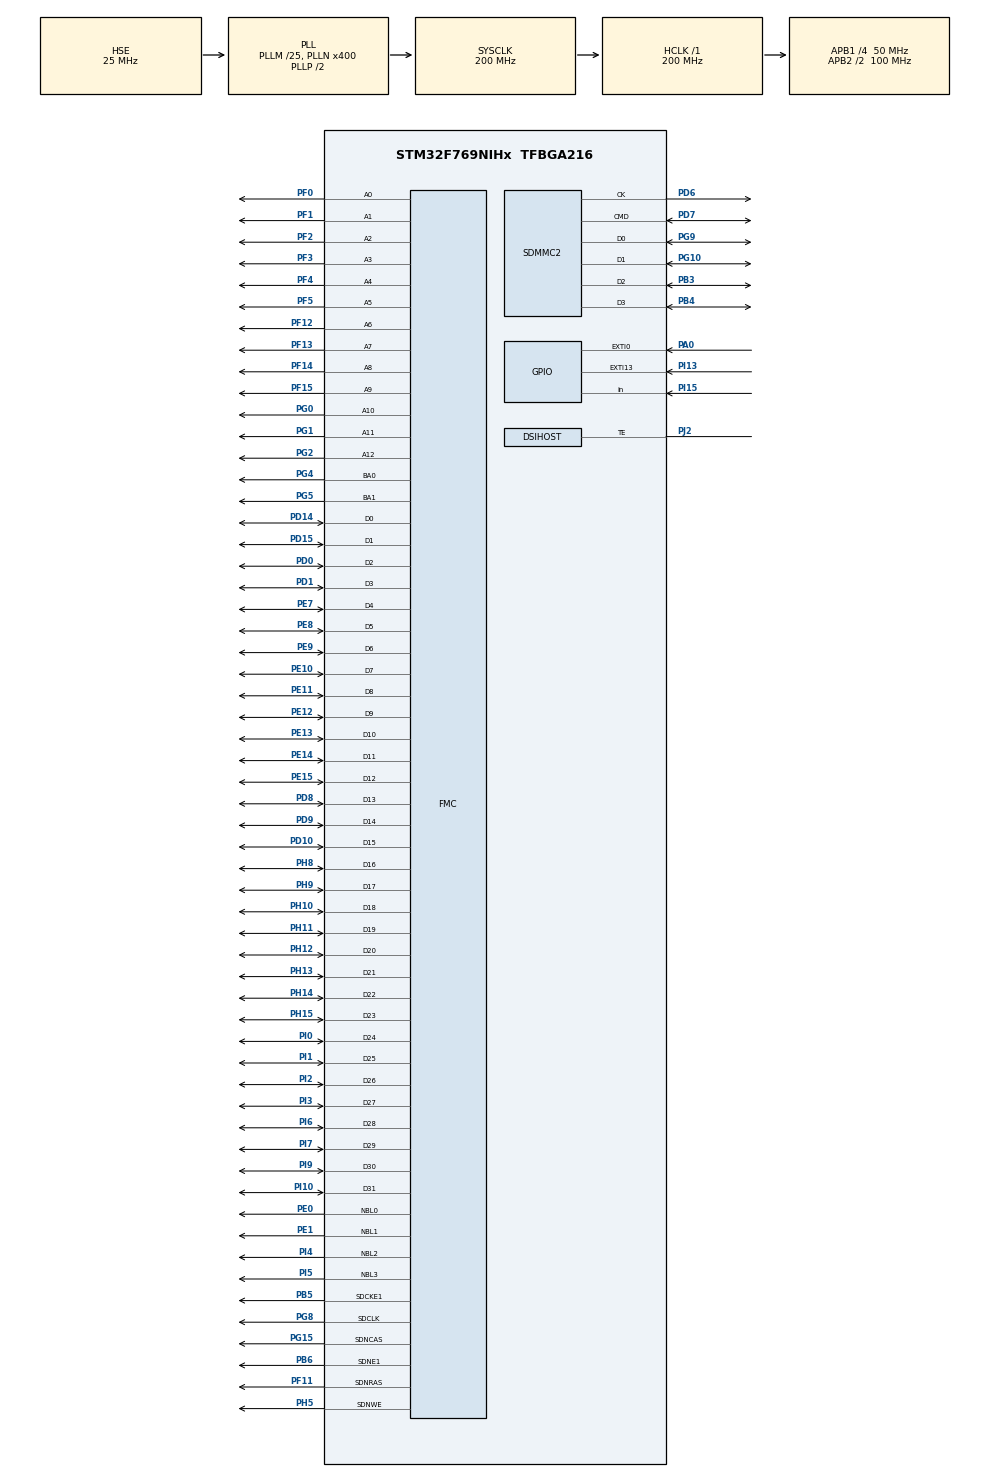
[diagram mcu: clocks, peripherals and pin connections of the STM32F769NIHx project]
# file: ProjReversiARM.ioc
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ADC1.Channel-0\#ChannelRegularConversion=ADC_CHANNEL_TEMPSENSOR
ADC1.ContinuousConvMode=ENABLE
ADC1.EOCSelection=ADC_EOC_SEQ_CONV
ADC1.NbrOfConversionFlag=1
ADC1.Rank-0\#ChannelRegularConversion=1
ADC1.SamplingTime-0\#ChannelRegularConversion=ADC_SAMPLETIME_56CYCLES
ADC1.master=1
CORTEX_M7.CPU_DCache=Enabled
CORTEX_M7.CPU_ICache=Enabled
DSIHOST_CKN.Mode=DSIHost_Adapted_TE
DSIHOST_CKN.Signal=DSIHOST_CKN
DSIHOST_CKP.Mode=DSIHost_Adapted_TE
DSIHOST_CKP.Signal=DSIHOST_CKP
DSIHOST_D0N.Mode=DSIHost_Adapted_TE
DSIHOST_D0N.Signal=DSIHOST_D0N
DSIHOST_D0P.Mode=DSIHost_Adapted_TE
DSIHOST_D0P.Signal=DSIHOST_D0P
DSIHOST_D1N.Mode=DSIHost_Adapted_TE
DSIHOST_D1N.Signal=DSIHOST_D1N
DSIHOST_D1P.Mode=DSIHost_Adapted_TE
DSIHOST_D1P.Signal=DSIHOST_D1P
FATFS.BSP.number=1
FATFS0.BSP.STBoard=false
FATFS0.BSP.api=Unknown
FATFS0.BSP.i2caddr=0
FATFS0.BSP.instance=PI15
FATFS0.BSP.ip=GPIO
FATFS0.BSP.mode=Input
FATFS0.BSP.name=Detect_SDIO
FATFS0.BSP.solution=PI15
Mcu.Family=STM32F7
Mcu.Name=STM32F769NIHx
Mcu.Package=TFBGA216
NVIC.EXTI0_IRQn=true\:0\:0\:false\:false\:true\:true\:true
NVIC.EXTI15_10_IRQn=true\:0\:0\:false\:false\:true\:true\:true
NVIC.PriorityGroup=NVIC_PRIORITYGROUP_4
NVIC.TIM6_DAC_IRQn=true\:0\:0\:false\:false\:true\:true\:true
NVIC.TIM7_IRQn=true\:0\:0\:false\:false\:true\:true\:true
PA0/WKUP.Signal=GPXTI0
PB3.Mode=SD_4_bits_Wide_bus
PB3.Signal=SDMMC2_D2
PB4.Mode=SD_4_bits_Wide_bus
PB4.Signal=SDMMC2_D3
PB5.Mode=SdramChipSelect2_1
PB5.Signal=FMC_SDCKE1
PB6.Mode=SdramChipSelect2_1
PB6.Signal=FMC_SDNE1
PD0.Signal=FMC_D2_DA2
PD1.Signal=FMC_D3_DA3
PD10.Signal=FMC_D15_DA15
PD14.Signal=FMC_D0_DA0
PD15.Signal=FMC_D1_DA1
PD6.Mode=SD_4_bits_Wide_bus
PD6.Signal=SDMMC2_CK
PD7.Mode=SD_4_bits_Wide_bus
PD7.Signal=SDMMC2_CMD
PD8.Signal=FMC_D13_DA13
PD9.Signal=FMC_D14_DA14
PE0.Signal=FMC_NBL0
PE1.Signal=FMC_NBL1
PE10.Signal=FMC_D7_DA7
PE11.Signal=FMC_D8_DA8
PE12.Signal=FMC_D9_DA9
PE13.Signal=FMC_D10_DA10
PE14.Signal=FMC_D11_DA11
PE15.Signal=FMC_D12_DA12
PE7.Signal=FMC_D4_DA4
PE8.Signal=FMC_D5_DA5
PE9.Signal=FMC_D6_DA6
PF0.Signal=FMC_A0
PF1.Signal=FMC_A1
PF11.Signal=FMC_SDNRAS
PF12.Signal=FMC_A6
PF13.Signal=FMC_A7
PF14.Signal=FMC_A8
PF15.Signal=FMC_A9
PF2.Signal=FMC_A2
PF3.Signal=FMC_A3
PF4.Signal=FMC_A4
PF5.Signal=FMC_A5
PG0.Signal=FMC_A10
PG1.Signal=FMC_A11
PG10.Mode=SD_4_bits_Wide_bus
PG10.Signal=SDMMC2_D1
PG15.Signal=FMC_SDNCAS
PG2.Signal=FMC_A12
PG4.Signal=FMC_A14_BA0
PG5.Signal=FMC_A15_BA1
PG8.Signal=FMC_SDCLK
PG9.Mode=SD_4_bits_Wide_bus
PG9.Signal=SDMMC2_D0
PH0/OSC_IN.Mode=HSE-External-Oscillator
PH0/OSC_IN.Signal=RCC_OSC_IN
PH1/OSC_OUT.Mode=HSE-External-Oscillator
PH1/OSC_OUT.Signal=RCC_OSC_OUT
PH10.Signal=FMC_D18
PH11.Signal=FMC_D19
PH12.Signal=FMC_D20
PH13.Signal=FMC_D21
PH14.Signal=FMC_D22
PH15.Signal=FMC_D23
PH5.Signal=FMC_SDNWE
PH8.Signal=FMC_D16
PH9.Signal=FMC_D17
PI0.Signal=FMC_D24
PI1.Signal=FMC_D25
PI10.Signal=FMC_D31
PI13.Signal=GPXTI13
PI15.Signal=GPIO_Input
PI2.Signal=FMC_D26
PI3.Signal=FMC_D27
PI4.Signal=FMC_NBL2
PI5.Signal=FMC_NBL3
PI6.Signal=FMC_D28
PI7.Signal=FMC_D29
PI9.Signal=FMC_D30
PJ2.Mode=DSIHost_Adapted_TE
PJ2.Signal=DSIHOST_TE
ProjectManager.HeapSize=0x200
ProjectManager.StackSize=0x400
ProjectManager.TargetToolchain=STM32CubeIDE
RCC.AHBFreq_Value=200000000
RCC.APB1CLKDivider=RCC_HCLK_DIV4
RCC.APB1Freq_Value=50000000
RCC.APB1TimFreq_Value=100000000
RCC.APB2CLKDivider=RCC_HCLK_DIV2
RCC.APB2Freq_Value=100000000
RCC.APB2TimFreq_Value=200000000
RCC.CortexFreq_Value=200000000
RCC.HCLKFreq_Value=200000000
RCC.HSE_VALUE=25000000
RCC.HSI_VALUE=16000000
RCC.LSE_VALUE=32768
RCC.PLLI2SN=96
RCC.PLLM=25
RCC.PLLN=400
RCC.PLLQ=8
RCC.PLLSourceVirtual=RCC_PLLSOURCE_HSE
RCC.SDMMC2ClockSelection=RCC_SDMMC2CLKSOURCE_CLK48
RCC.SYSCLKFreq_VALUE=200000000
RCC.SYSCLKSource=RCC_SYSCLKSOURCE_PLLCLK
RCC.USBFreq_Value=50000000
RCC.VCOOutputFreq_Value=400000000
SH.FMC_A0.0=FMC_A0,13b-sda1
SH.FMC_A1.0=FMC_A1,13b-sda1
SH.FMC_A10.0=FMC_A10,13b-sda1
SH.FMC_A11.0=FMC_A11,13b-sda1
SH.FMC_A12.0=FMC_A12,13b-sda1
SH.FMC_A14_BA0.0=FMC_BA0,FourSdramBanks1
SH.FMC_A15_BA1.0=FMC_BA1,FourSdramBanks1
SH.FMC_A2.0=FMC_A2,13b-sda1
SH.FMC_A3.0=FMC_A3,13b-sda1
SH.FMC_A4.0=FMC_A4,13b-sda1
SH.FMC_A5.0=FMC_A5,13b-sda1
SH.FMC_A6.0=FMC_A6,13b-sda1
SH.FMC_A7.0=FMC_A7,13b-sda1
SH.FMC_A8.0=FMC_A8,13b-sda1
SH.FMC_A9.0=FMC_A9,13b-sda1
SH.FMC_D0_DA0.0=FMC_D0,sd-32b-d1
SH.FMC_D10_DA10.0=FMC_D10,sd-32b-d1
SH.FMC_D11_DA11.0=FMC_D11,sd-32b-d1
SH.FMC_D12_DA12.0=FMC_D12,sd-32b-d1
SH.FMC_D13_DA13.0=FMC_D13,sd-32b-d1
SH.FMC_D14_DA14.0=FMC_D14,sd-32b-d1
SH.FMC_D15_DA15.0=FMC_D15,sd-32b-d1
SH.FMC_D16.0=FMC_D16,sd-32b-d1
SH.FMC_D17.0=FMC_D17,sd-32b-d1
SH.FMC_D18.0=FMC_D18,sd-32b-d1
SH.FMC_D19.0=FMC_D19,sd-32b-d1
SH.FMC_D1_DA1.0=FMC_D1,sd-32b-d1
SH.FMC_D20.0=FMC_D20,sd-32b-d1
SH.FMC_D21.0=FMC_D21,sd-32b-d1
SH.FMC_D22.0=FMC_D22,sd-32b-d1
SH.FMC_D23.0=FMC_D23,sd-32b-d1
SH.FMC_D24.0=FMC_D24,sd-32b-d1
SH.FMC_D25.0=FMC_D25,sd-32b-d1
SH.FMC_D26.0=FMC_D26,sd-32b-d1
SH.FMC_D27.0=FMC_D27,sd-32b-d1
SH.FMC_D28.0=FMC_D28,sd-32b-d1
SH.FMC_D29.0=FMC_D29,sd-32b-d1
SH.FMC_D2_DA2.0=FMC_D2,sd-32b-d1
SH.FMC_D30.0=FMC_D30,sd-32b-d1
SH.FMC_D31.0=FMC_D31,sd-32b-d1
SH.FMC_D3_DA3.0=FMC_D3,sd-32b-d1
SH.FMC_D4_DA4.0=FMC_D4,sd-32b-d1
SH.FMC_D5_DA5.0=FMC_D5,sd-32b-d1
SH.FMC_D6_DA6.0=FMC_D6,sd-32b-d1
SH.FMC_D7_DA7.0=FMC_D7,sd-32b-d1
SH.FMC_D8_DA8.0=FMC_D8,sd-32b-d1
SH.FMC_D9_DA9.0=FMC_D9,sd-32b-d1
SH.FMC_NBL0.0=FMC_NBL0,Sd4ByteEnable1
SH.FMC_NBL1.0=FMC_NBL1,Sd4ByteEnable1
SH.FMC_NBL2.0=FMC_NBL2,Sd4ByteEnable1
SH.FMC_NBL3.0=FMC_NBL3,Sd4ByteEnable1
SH.FMC_SDCLK.0=FMC_SDCLK,13b-sda1
SH.FMC_SDNCAS.0=FMC_SDNCAS,13b-sda1
SH.FMC_SDNRAS.0=FMC_SDNRAS,13b-sda1
SH.FMC_SDNWE.0=FMC_SDNWE,13b-sda1
TIM6.Period=9999
TIM6.Prescaler=9999
TIM7.Period=9999
TIM7.Prescaler=9999
VP_ADC1_TempSens_Input.Mode=IN-TempSens
VP_DMA2D_VS_DMA2D.Mode=DMA2D_Activate
VP_FATFS_VS_SDIO.Mode=SDIO
VP_LTDC_DSIMode.Mode=RGB888
VP_TIM6_VS_ClockSourceINT.Mode=Enable_Timer
VP_TIM7_VS_ClockSourceINT.Mode=Enable_Timer
board=STM32F769I-DISC1

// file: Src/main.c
/* USER CODE BEGIN Header */
/**
  ******************************************************************************
  * @file           : main.c
  * @brief          : Main program body
  ******************************************************************************
  * @attention
  *
  * <h2><center>&copy; Copyright (c) 2019 STMicroelectronics.
  * All rights reserved.</center></h2>
  *
  * This software component is licensed by ST under BSD 3-Clause license,
  * the "License"; You may not use this file except in compliance with the
  * License. You may obtain a copy of the License at:
  *                        opensource.org/licenses/BSD-3-Clause
  *
  ******************************************************************************
  */
/* USER CODE END Header */

#include "main.h"
#include "fatfs.h"

/* USER CODE BEGIN Includes */
#include <stdio.h>
#include "stm32f769i_discovery_lcd.h"
#include "stm32f769i_discovery_ts.h"
#include "stm32f769i_discovery.h"
#include <stdbool.h>
#include "imgBlack.h"
//#include "imgRed.h"
/* USER CODE END Includes */

/* USER CODE BEGIN PD */
#define TEMP_REFRESH_PERIOD   1000    /* Internal temperature refresh period */
#define MAX_CONVERTED_VALUE   4095    /* Max converted value */
#define AMBIENT_TEMP            25    /* Ambient Temperature */
#define VSENS_AT_AMBIENT_TEMP  760    /* VSENSE value (mv) at ambient temperature */
#define AVG_SLOPE               25    /* Avg_Solpe multiply by 10 */
#define VREF                   3300
#define TAMQUADRADO				56.3
#define X				TS_State.touchX[0]
#define Y				TS_State.touchY[0]
#define RAIO					22
/* USER CODE END PD */

ADC_HandleTypeDef hadc1;

DMA2D_HandleTypeDef hdma2d;

DSI_HandleTypeDef hdsi;

LTDC_HandleTypeDef hltdc;

SD_HandleTypeDef hsd2;

TIM_HandleTypeDef htim6;
TIM_HandleTypeDef htim7;

SDRAM_HandleTypeDef hsdram1;

/* USER CODE BEGIN PV */

TS_StateTypeDef TS_State;

volatile uint32_t ConvertedValue;
volatile uint8_t tempCnt = 0;		//contador para alterar a temperatura a cada 2 segundos
volatile int timeTotal=0;			//contador do tempo total de jogo
volatile uint8_t seconds = 0;		//contador para converter o tempo total em segundos
volatile uint8_t minutes=0;			//contador para os minutos do tempo total
volatile uint8_t ctdown=20;			//contador do tempo de jogada
volatile uint8_t touchCircle=0;		//contador de toques da peça branca
volatile uint8_t touchFill=0;		//contador de toques da peça preta
volatile uint8_t ctJogadas=0;		//contador para o numero de jogadas
volatile uint8_t ctTimeOut=3;		//contador para o numero de timeouts
volatile uint8_t ctReset=0;			//contador para o umero de resets

long int JTemp;						//variavel para guardar a temperatura
char string[50];
int reset=0;
int passouTempo=0;

//FLAGS
volatile uint8_t DBFLAG=0; 				//flag para debouncing
bool TEMPFLAG=false;					//flag para entrar na temperatura
volatile uint8_t PLAYERFLAG=0;			//flag para trocar jogador
volatile uint8_t TIMEFLAG=0;			//flag para contador decrescente
volatile uint8_t MENUFLAG=0;			//flag para entrar no menu
volatile uint8_t UPDATE_DISPLAY = 0;	//flag para update display
volatile uint8_t LETSPLAY=0;			//flag para iniciar o jogo
bool VERMELHAJOGOU=false;				//flag para saber se branca jogou numa celula
bool PRETAJOGOU=false;					//flag para saber se preta jogou numa celula

/* USER CODE END PV */

void SystemClock_Config(void);
static void MX_GPIO_Init(void);
static void MX_ADC1_Init(void);
static void MX_DMA2D_Init(void);
static void MX_DSIHOST_DSI_Init(void);
static void MX_FMC_Init(void);
static void MX_LTDC_Init(void);
static void MX_SDMMC2_SD_Init(void);
static void MX_TIM6_Init(void);
static void MX_TIM7_Init(void);
/* USER CODE BEGIN PFP */
static void LCD_Config();
/* USER CODE END PFP */

/* USER CODE BEGIN 0 */
void HAL_GPIO_EXTI_Callback(uint16_t GPIO_Pin){

	if(GPIO_Pin==GPIO_PIN_0){
		reset=1;
	}

	if(GPIO_Pin==GPIO_PIN_13)
	{
		if(DBFLAG == 0)
		{
			DBFLAG=1;
			UPDATE_DISPLAY = 1;
			BSP_TS_GetState(&TS_State);
		}
	}
}

//GOAL 1 //temperatura
void temperatura() {
	uint32_t ConvertedValue;
	char desc[100];

	if(tempCnt >= 2)
	{
		tempCnt = 0;

		HAL_StatusTypeDef status = HAL_ADC_PollForConversion(&hadc1, TEMP_REFRESH_PERIOD);
		if (status == HAL_OK) {
			ConvertedValue = HAL_ADC_GetValue(&hadc1); //get value
			JTemp = ((((ConvertedValue * VREF) / MAX_CONVERTED_VALUE)- VSENS_AT_AMBIENT_TEMP) * 10 / AVG_SLOPE) + AMBIENT_TEMP;

			/* Display the Temperature Value on the LCD */
			sprintf(desc, "Temp: %ldC", JTemp);
			//BSP_LCD_FillRect(BSP_LCD_GetXSize()-160, 0, (uint8_t *) desc, LEFT_MODE);
			BSP_LCD_SetBackColor(LCD_COLOR_YELLOW);
			BSP_LCD_DisplayStringAt(BSP_LCD_GetXSize()-160, 0, (uint8_t *) desc, LEFT_MODE);
			BSP_LCD_ClearStringLine(BSP_LCD_GetXSize()-160);
		}
	}
}

//GOAL6 //saveSD
void saveSD(){

	char toques[500];
	uint nbytes;

	sprintf(toques,"Peça vermelha: %d toques Peça preta: %d toques / Tempo decorrido %02d:%02d / Temperatura: %ldC / Nº de resets: %d",touchCircle, touchFill, minutes, seconds, JTemp, ctReset);
	/*sprintf(toques,"Peca branca: %d toques / ",touchCircle);
	sprintf(toques,"Peca preta: %d toques / ",touchFill);
	sprintf(toques,"Tempo decorrido %02d:%02d",minutes,seconds);*/

	if(f_mount(&SDFatFS, SDPath, 0)!= FR_OK)
		Error_Handler();
	if(f_open(&SDFile, "toques.txt", FA_WRITE | FA_OPEN_ALWAYS) != FR_OK)
		Error_Handler();
	else
		BSP_LED_Toggle(LED_GREEN);
	if(f_write(&SDFile, toques, strlen(toques), &nbytes) != FR_OK)
		Error_Handler();
	else{
		BSP_LED_Toggle(LED_GREEN);
		HAL_Delay(250);
	}

	f_close(&SDFile);
}

/*void readSD(){
	if(f_mount(&SDFatFS, SDPath, 0)!= FR_OK)
		Error_Handler();
	if(f_open(&SDFile, "toques.txt", FA_WRITE | FA_OPEN_ALWAYS) != FR_OK){
		Error_Handler();
		BSP_LED_Toggle(LED_GREEN);
		HAL_Delay(250);
	}
	if(f_read(&SDFile, toques, strlen(toques), &nbytes) != FR_OK){
		Error_Handler();
		BSP_LED_Toggle(LED_GREEN);
		HAL_Delay(250);
	}
	BSP_LCD_DisplayStringAtLine(1, (uint8_t*)toques);
	f_close(&SDFile);
}*/

void drawPiece(int i, int j){

	if(DBFLAG == 1){
		HAL_Delay(100);
		DBFLAG=0;

		if(PLAYERFLAG==0){
			BSP_LCD_SetTextColor(LCD_COLOR_RED);
			BSP_LCD_FillCircle(i+(TAMQUADRADO/2), j+(TAMQUADRADO/2), RAIO);
			PLAYERFLAG=1;
			touchCircle++;
			ctJogadas++;
			VERMELHAJOGOU=true;
			BSP_LCD_SetTextColor(LCD_COLOR_BLACK);
		}
		else{
			BSP_LCD_SetTextColor(LCD_COLOR_BLACK);
			BSP_LCD_FillCircle(i+(TAMQUADRADO/2), j+(TAMQUADRADO/2), RAIO);
			PLAYERFLAG=0;
			touchFill++;
			ctJogadas++;
			PRETAJOGOU=true;
			BSP_LCD_SetTextColor(LCD_COLOR_BLACK);
		}
		if(ctJogadas==11){
			saveSD();
		}
	}
}

//GOAL 3 //limites
void limites()
{
	int i=0, j=0;

	/*memset(string, '\0', 50);
	sprintf(string, "X= %d", X);
	BSP_LCD_ClearStringLine(4);
	BSP_LCD_DisplayStringAtLine(4, (uint8_t *)string);

	memset(string, '\0', 50);
	sprintf(string, "Y= %d", Y);
	BSP_LCD_ClearStringLine(5);
	BSP_LCD_DisplayStringAtLine(5, (uint8_t *)string);*/

	for(i=0; i<BSP_LCD_GetXSize()-360; i+=TAMQUADRADO)
	{
		for(j=30;j<BSP_LCD_GetYSize()-30;j+=TAMQUADRADO)
		{
			if(X<BSP_LCD_GetXSize()-360  && X >= 0 && Y>30 && Y<BSP_LCD_GetYSize())
			{
				if(X>i && X<(i+TAMQUADRADO) && Y>j && Y<(j+TAMQUADRADO))
				{
					drawPiece(i,j);
					break;
				}
			}
			else
				DBFLAG=0;
		}
	}
}

//GOAL 2 //tab
void tab(){
	int i=0, j=30;
	/*int x=BSP_LCD_GetXSize()/2;
	int y=BSP_LCD_GetYSize();*/

	for(i=0; i<BSP_LCD_GetXSize()-360; i+=TAMQUADRADO)
	{
		/*BSP_LCD_SetTextColor(LCD_COLOR_GREEN);
		BSP_LCD_FillRect(i, 30, TAMQUADRADO, TAMQUADRADO);
		BSP_LCD_SetTextColor(LCD_COLOR_BLACK);*/
		BSP_LCD_DrawRect(i, 30, TAMQUADRADO, TAMQUADRADO);

		for(j=30;j<BSP_LCD_GetYSize()-30;j+=TAMQUADRADO){
			/*BSP_LCD_SetTextColor(LCD_COLOR_GREEN);
			BSP_LCD_FillRect(i, j, TAMQUADRADO, TAMQUADRADO);
			BSP_LCD_SetTextColor(LCD_COLOR_BLACK);*/
			BSP_LCD_DrawRect(i, j, TAMQUADRADO, TAMQUADRADO);
		}
		if(i>168.9 && i<225.2 && j>142.6 && j<198.9)
			BSP_LCD_DrawCircle(i+(TAMQUADRADO/2), j+(TAMQUADRADO/2), RAIO);
	}

	//limites();
}

//GOAL 4

//GOAL 5 //menu
void menu(){

	char escolha[50];
	BSP_LCD_Clear(LCD_COLOR_WHITE);
	MENUFLAG=1;

	sprintf(escolha,"PLAYER vs PLAYER");
	BSP_LCD_DrawRect(BSP_LCD_GetXSize()-565, BSP_LCD_GetYSize()-400, 350, 60);
	BSP_LCD_DisplayStringAt(BSP_LCD_GetXSize()-525, BSP_LCD_GetYSize()-375, (uint8_t *) escolha, LEFT_MODE);
	BSP_LCD_ClearStringLine(BSP_LCD_GetXSize()-525);

	sprintf(escolha, "PLAYER vs CPU");
	BSP_LCD_DrawRect(BSP_LCD_GetXSize()-540, BSP_LCD_GetYSize()-265, 300, 60);
	BSP_LCD_DisplayStringAt(BSP_LCD_GetXSize()-500, BSP_LCD_GetYSize()-240, (uint8_t *) escolha, LEFT_MODE);
	BSP_LCD_ClearStringLine(BSP_LCD_GetXSize()-500);

	while(DBFLAG != 1)	//Enquanto n tocar no lcd
	{
		HAL_Delay(100);
	}

	if(X>=BSP_LCD_GetXSize()-565 && X<=BSP_LCD_GetYSize()-25 && Y>=BSP_LCD_GetYSize()-400 && Y<=BSP_LCD_GetYSize()-340)
	{
		MENUFLAG=0;
		UPDATE_DISPLAY=1;
		//LCD_Config();
		//LETSPLAY=1;
		BSP_LCD_Clear(LCD_COLOR_WHITE);
		//joga();
	}
	/*if(X==BSP_LCD_GetXSize()-500 && Y==BSP_LCD_GetYSize()-240){
	 	MENUFLAG=1;
	 	UPDATE_DISPLAY=1;
		jogaAI();
	}*/

}

//GOAL7	//countdown
void countDown()
{
	char t[50];
	char to[50];
	char win[50];

	if(PLAYERFLAG==0){
		sprintf(t, "Countdown: %02ds", ctdown);
		sprintf(to,"Timeouts %d", ctTimeOut);
		if(ctdown>10){
			BSP_LCD_SetBackColor(LCD_COLOR_GREEN);
			BSP_LCD_DisplayStringAt(BSP_LCD_GetXSize()-290, 55, (uint8_t *)t, LEFT_MODE);
			BSP_LCD_SetBackColor(LCD_COLOR_WHITE);
			BSP_LCD_DisplayStringAt(BSP_LCD_GetXSize()-290, 85, (uint8_t *)to, LEFT_MODE);
		}
		if(ctdown<=10 && ctdown>5){
			BSP_LCD_SetBackColor(LCD_COLOR_YELLOW);
			BSP_LCD_DisplayStringAt(BSP_LCD_GetXSize()-290, 55, (uint8_t *)t, LEFT_MODE);
			BSP_LCD_SetBackColor(LCD_COLOR_WHITE);
			BSP_LCD_DisplayStringAt(BSP_LCD_GetXSize()-290, 85, (uint8_t *)to, LEFT_MODE);
		}
		if(ctdown<=5){
			BSP_LCD_SetBackColor(LCD_COLOR_RED);
			BSP_LCD_DisplayStringAt(BSP_LCD_GetXSize()-290, 55, (uint8_t *)t, LEFT_MODE);
			BSP_LCD_SetBackColor(LCD_COLOR_WHITE);
			BSP_LCD_DisplayStringAt(BSP_LCD_GetXSize()-290, 85, (uint8_t *)to, LEFT_MODE);
		}
		if(ctdown==0){
			passouTempo++;
			ctdown=20;
			ctTimeOut--;
			PLAYERFLAG=1;
		}
		if(ctTimeOut==0){
			BSP_LCD_SetBackColor(LCD_COLOR_WHITE);
			sprintf(win,"BLACK WINS");
			BSP_LCD_DisplayStringAt(BSP_LCD_GetXSize()-290, BSP_LCD_GetYSize()/2, (uint8_t *)win, LEFT_MODE);
			//BSP_LCD_Clear(LCD_COLOR_WHITE);
			BSP_LCD_DrawBitmap(BSP_LCD_GetXSize()-290,BSP_LCD_GetYSize()/2,(uint8_t*) stlogo);
			LETSPLAY=0;
			saveSD();
		}
	}

	if(PLAYERFLAG==1){
		sprintf(t, "Countdown: %02ds", ctdown);
		sprintf(to,"Timeouts %d", ctTimeOut);
		if(ctdown>10){
			BSP_LCD_SetBackColor(LCD_COLOR_GREEN);
			BSP_LCD_DisplayStringAt(BSP_LCD_GetXSize()-290, 55, (uint8_t *)t, LEFT_MODE);
			BSP_LCD_SetBackColor(LCD_COLOR_WHITE);
			BSP_LCD_DisplayStringAt(BSP_LCD_GetXSize()-290, 85, (uint8_t *)to, LEFT_MODE);
		}
		if(ctdown<=10 && ctdown>5){
			BSP_LCD_SetBackColor(LCD_COLOR_YELLOW);
			BSP_LCD_DisplayStringAt(BSP_LCD_GetXSize()-290, 55, (uint8_t *)t, LEFT_MODE);
			BSP_LCD_SetBackColor(LCD_COLOR_WHITE);
			BSP_LCD_DisplayStringAt(BSP_LCD_GetXSize()-290, 85, (uint8_t *)to, LEFT_MODE);
		}
		if(ctdown<=5){
			BSP_LCD_SetBackColor(LCD_COLOR_RED);
			BSP_LCD_DisplayStringAt(BSP_LCD_GetXSize()-290, 55, (uint8_t *)t, LEFT_MODE);
			BSP_LCD_SetBackColor(LCD_COLOR_WHITE);
			BSP_LCD_DisplayStringAt(BSP_LCD_GetXSize()-290, 85, (uint8_t *)to, LEFT_MODE);
		}
		if(ctdown==0){
			ctdown=20;
			ctTimeOut--;
			PLAYERFLAG=0;
		}
		if(ctTimeOut==0){
			BSP_LCD_SetBackColor(LCD_COLOR_WHITE);
			sprintf(win,"RED WINS");
			BSP_LCD_DisplayStringAt(BSP_LCD_GetXSize()-290, BSP_LCD_GetYSize()/2, (uint8_t *)win, LEFT_MODE);
			//BSP_LCD_Clear(LCD_COLOR_WHITE);
			//BSP_LCD_DrawBitmap(BSP_LCD_GetXSize()-290,BSP_LCD_GetYSize()/2,(uint8_t*) stlogo);
			LETSPLAY=0;
			saveSD();
		}
	}
	BSP_LCD_SetBackColor(LCD_COLOR_WHITE);
}

//GOAL8	//tempoJogo
void tempoJogo(){

	char t[50];

	if(TIMEFLAG==0)
	{
		sprintf(t, "Total Time: %02d:%02d", minutes, seconds);
		BSP_LCD_SetBackColor(LCD_COLOR_WHITE);
		BSP_LCD_DisplayStringAt(BSP_LCD_GetXSize()-290, 31, (uint8_t *)t, LEFT_MODE);

		if(seconds>59)
		{
			minutes++;
			seconds=0;
		}
	}
}

//GOAL 9	//restart
void restart(){
	BSP_LCD_Clear(LCD_COLOR_WHITE);
	menu();

	ConvertedValue;
	tempCnt = 0;
	timeTotal=0;
	seconds = 0;
	minutes=0;
	ctdown=20;
	touchCircle=0;
	touchFill=0;
	ctJogadas=0;
	ctTimeOut=3;
	ctReset=0;

	reset=0;
	passouTempo=0;

	//FLAGS
	DBFLAG=0;
	TEMPFLAG=false;
	PLAYERFLAG=0;
	TIMEFLAG=0;
	MENUFLAG=0;
	UPDATE_DISPLAY = 0;
	//LETSPLAY=0;
	VERMELHAJOGOU=false;
	PRETAJOGOU=false;
}

//funcoes de apoio
void joga(){
	//BSP_LCD_Clear(LCD_COLOR_WHITE);
	temperatura();
	tab();
	tempoJogo();
	if(ctJogadas==11){
		saveSD();
		//restart();
		menu();
	}
	if(reset==1)
	  restart();
}

void jogaAI(){

}

void getTouch(){
	if(DBFLAG == 1)
		  {
			  DBFLAG = 0;
			  memset(string, '\0', 50);
			  sprintf(string, "X= %d", TS_State.touchX[0]);
			  BSP_LCD_ClearStringLine(4);
			  BSP_LCD_DisplayStringAtLine(4, (uint8_t *)string);

			  memset(string, '\0', 50);
			  sprintf(string, "Y= %d", TS_State.touchY[0]);
			  BSP_LCD_ClearStringLine(5);
			  BSP_LCD_DisplayStringAtLine(5, (uint8_t *)string);

		  }
}
/*void header(){
	BSP_LCD_SetTextColor(LCD_COLOR_WHITE);
	BSP_LCD_SetBackColor(LCD_COLOR_BLUE);
	BSP_LCD_SetFont(&Font24);
	BSP_LCD_DisplayStringAt(0, 5, (uint8_t *)"REVERSI PROJECT", CENTER_MODE);
}*/

/* USER CODE END 0 */

int main(void)
{

  /* Enable I-Cache---------------------------------------------------------*/
  SCB_EnableICache();

  /* Enable D-Cache---------------------------------------------------------*/
  SCB_EnableDCache();

  /* MCU Configuration--------------------------------------------------------*/

  /* Reset of all peripherals, Initializes the Flash interface and the Systick. */
  HAL_Init();

  /* Configure the system clock */
  SystemClock_Config();

  /* Initialize all configured peripherals */
  MX_GPIO_Init();
  MX_ADC1_Init();
  MX_DMA2D_Init();
  MX_DSIHOST_DSI_Init();
  MX_FMC_Init();
  MX_LTDC_Init();
  MX_SDMMC2_SD_Init();
  MX_TIM6_Init();
  MX_TIM7_Init();
  MX_FATFS_Init();
  /* USER CODE BEGIN 2 */
  LCD_Config();
  	//BSP_LED_Init(LED1);

  BSP_TS_Init(BSP_LCD_GetXSize(), BSP_LCD_GetYSize());
  BSP_TS_ITConfig();

  	//start do adc
  	HAL_ADC_Start(&hadc1);
  	//HAL_ADC_Start_IT(&hadc3);

  	HAL_TIM_Base_Start_IT(&htim6);
  	HAL_TIM_Base_Start_IT(&htim7);

  	//tab();	//TODO: trocar por menu
  	menu();
  /* USER CODE END 2 */

  /* Infinite loop */
  /* USER CODE BEGIN WHILE */
  while (1)
  {
	  /*if(MENUFLAG==0)
		  menu();*/
	  //joga();
	  temperatura();	//Flags internas: 2s update
	  //if(LETSPLAY==1){
	  tempoJogo();		//Counter 1 sec update
	  countDown();		//Counter 1 sec update
	  //}

	  if(UPDATE_DISPLAY == 1)
	  {
		  UPDATE_DISPLAY = 0;
		  tab();
		  limites();
	  }

	  if(reset==1){
	  	  restart();
	  	  ctReset++;
	  }

    /* USER CODE END WHILE */

    /* USER CODE BEGIN 3 */
  }
  //LETSPLAY=0;
  /* USER CODE END 3 */
}

void SystemClock_Config(void)
{
  RCC_OscInitTypeDef RCC_OscInitStruct = {0};
  RCC_ClkInitTypeDef RCC_ClkInitStruct = {0};
  RCC_PeriphCLKInitTypeDef PeriphClkInitStruct = {0};

  /** Configure the main internal regulator output voltage
  */
  __HAL_RCC_PWR_CLK_ENABLE();
  __HAL_PWR_VOLTAGESCALING_CONFIG(PWR_REGULATOR_VOLTAGE_SCALE1);
  /** Initializes the CPU, AHB and APB busses clocks
  */
  RCC_OscInitStruct.OscillatorType = RCC_OSCILLATORTYPE_HSE;
  RCC_OscInitStruct.HSEState = RCC_HSE_ON;
  RCC_OscInitStruct.PLL.PLLState = RCC_PLL_ON;
  RCC_OscInitStruct.PLL.PLLSource = RCC_PLLSOURCE_HSE;
  RCC_OscInitStruct.PLL.PLLM = 25;
  RCC_OscInitStruct.PLL.PLLN = 400;
  RCC_OscInitStruct.PLL.PLLP = RCC_PLLP_DIV2;
  RCC_OscInitStruct.PLL.PLLQ = 8;
  if (HAL_RCC_OscConfig(&RCC_OscInitStruct) != HAL_OK)
  {
    Error_Handler();
  }
  /** Activate the Over-Drive mode
  */
  if (HAL_PWREx_EnableOverDrive() != HAL_OK)
  {
    Error_Handler();
  }
  /** Initializes the CPU, AHB and APB busses clocks
  */
  RCC_ClkInitStruct.ClockType = RCC_CLOCKTYPE_HCLK|RCC_CLOCKTYPE_SYSCLK
                              |RCC_CLOCKTYPE_PCLK1|RCC_CLOCKTYPE_PCLK2;
  RCC_ClkInitStruct.SYSCLKSource = RCC_SYSCLKSOURCE_PLLCLK;
  RCC_ClkInitStruct.AHBCLKDivider = RCC_SYSCLK_DIV1;
  RCC_ClkInitStruct.APB1CLKDivider = RCC_HCLK_DIV4;
  RCC_ClkInitStruct.APB2CLKDivider = RCC_HCLK_DIV2;

  if (HAL_RCC_ClockConfig(&RCC_ClkInitStruct, FLASH_LATENCY_6) != HAL_OK)
  {
    Error_Handler();
  }
  PeriphClkInitStruct.PeriphClockSelection = RCC_PERIPHCLK_LTDC|RCC_PERIPHCLK_SDMMC2
                              |RCC_PERIPHCLK_CLK48;
  PeriphClkInitStruct.PLLSAI.PLLSAIN = 192;
  PeriphClkInitStruct.PLLSAI.PLLSAIR = 2;
  PeriphClkInitStruct.PLLSAI.PLLSAIQ = 2;
  PeriphClkInitStruct.PLLSAI.PLLSAIP = RCC_PLLSAIP_DIV2;
  PeriphClkInitStruct.PLLSAIDivQ = 1;
  PeriphClkInitStruct.PLLSAIDivR = RCC_PLLSAIDIVR_2;
  PeriphClkInitStruct.Clk48ClockSelection = RCC_CLK48SOURCE_PLL;
  PeriphClkInitStruct.Sdmmc2ClockSelection = RCC_SDMMC2CLKSOURCE_CLK48;
  if (HAL_RCCEx_PeriphCLKConfig(&PeriphClkInitStruct) != HAL_OK)
  {
    Error_Handler();
  }
}

static void MX_ADC1_Init(void)
{

  ADC_ChannelConfTypeDef sConfig = {0};

  /** Configure the global features of the ADC (Clock, Resolution, Data Alignment and number of conversion)
  */
  hadc1.Instance = ADC1;
  hadc1.Init.ClockPrescaler = ADC_CLOCK_SYNC_PCLK_DIV4;
  hadc1.Init.Resolution = ADC_RESOLUTION_12B;
  hadc1.Init.ScanConvMode = DISABLE;
  hadc1.Init.ContinuousConvMode = ENABLE;
  hadc1.Init.DiscontinuousConvMode = DISABLE;
  hadc1.Init.ExternalTrigConvEdge = ADC_EXTERNALTRIGCONVEDGE_NONE;
  hadc1.Init.ExternalTrigConv = ADC_SOFTWARE_START;
  hadc1.Init.DataAlign = ADC_DATAALIGN_RIGHT;
  hadc1.Init.NbrOfConversion = 1;
  hadc1.Init.DMAContinuousRequests = DISABLE;
  hadc1.Init.EOCSelection = ADC_EOC_SEQ_CONV;
  if (HAL_ADC_Init(&hadc1) != HAL_OK)
  {
    Error_Handler();
  }
  /** Configure for the selected ADC regular channel its corresponding rank in the sequencer and its sample time.
  */
  sConfig.Channel = ADC_CHANNEL_TEMPSENSOR;
  sConfig.Rank = ADC_REGULAR_RANK_1;
  sConfig.SamplingTime = ADC_SAMPLETIME_56CYCLES;
  if (HAL_ADC_ConfigChannel(&hadc1, &sConfig) != HAL_OK)
  {
    Error_Handler();
  }

}

static void MX_DMA2D_Init(void)
{

  hdma2d.Instance = DMA2D;
  hdma2d.Init.Mode = DMA2D_M2M;
  hdma2d.Init.ColorMode = DMA2D_OUTPUT_ARGB8888;
  hdma2d.Init.OutputOffset = 0;
  hdma2d.LayerCfg[1].InputOffset = 0;
  hdma2d.LayerCfg[1].InputColorMode = DMA2D_INPUT_ARGB8888;
  hdma2d.LayerCfg[1].AlphaMode = DMA2D_NO_MODIF_ALPHA;
  hdma2d.LayerCfg[1].InputAlpha = 0;
  hdma2d.LayerCfg[1].AlphaInverted = DMA2D_REGULAR_ALPHA;
  hdma2d.LayerCfg[1].RedBlueSwap = DMA2D_RB_REGULAR;
  if (HAL_DMA2D_Init(&hdma2d) != HAL_OK)
  {
    Error_Handler();
  }
  if (HAL_DMA2D_ConfigLayer(&hdma2d, 1) != HAL_OK)
  {
    Error_Handler();
  }

}

static void MX_DSIHOST_DSI_Init(void)
{

  DSI_PLLInitTypeDef PLLInit = {0};
  DSI_HOST_TimeoutTypeDef HostTimeouts = {0};
  DSI_PHY_TimerTypeDef PhyTimings = {0};
  DSI_LPCmdTypeDef LPCmd = {0};
  DSI_CmdCfgTypeDef CmdCfg = {0};

  hdsi.Instance = DSI;
  hdsi.Init.AutomaticClockLaneControl = DSI_AUTO_CLK_LANE_CTRL_DISABLE;
  hdsi.Init.TXEscapeCkdiv = 4;
  hdsi.Init.NumberOfLanes = DSI_ONE_DATA_LANE;
  PLLInit.PLLNDIV = 20;
  PLLInit.PLLIDF = DSI_PLL_IN_DIV1;
  PLLInit.PLLODF = DSI_PLL_OUT_DIV1;
  if (HAL_DSI_Init(&hdsi, &PLLInit) != HAL_OK)
  {
    Error_Handler();
  }
  HostTimeouts.TimeoutCkdiv = 1;
  HostTimeouts.HighSpeedTransmissionTimeout = 0;
  HostTimeouts.LowPowerReceptionTimeout = 0;
  HostTimeouts.HighSpeedReadTimeout = 0;
  HostTimeouts.LowPowerReadTimeout = 0;
  HostTimeouts.HighSpeedWriteTimeout = 0;
  HostTimeouts.HighSpeedWritePrespMode = DSI_HS_PM_DISABLE;
  HostTimeouts.LowPowerWriteTimeout = 0;
  HostTimeouts.BTATimeout = 0;
  if (HAL_DSI_ConfigHostTimeouts(&hdsi, &HostTimeouts) != HAL_OK)
  {
    Error_Handler();
  }
  PhyTimings.ClockLaneHS2LPTime = 28;
  PhyTimings.ClockLaneLP2HSTime = 33;
  PhyTimings.DataLaneHS2LPTime = 15;
  PhyTimings.DataLaneLP2HSTime = 25;
  PhyTimings.DataLaneMaxReadTime = 0;
  PhyTimings.StopWaitTime = 0;
  if (HAL_DSI_ConfigPhyTimer(&hdsi, &PhyTimings) != HAL_OK)
  {
    Error_Handler();
  }
  if (HAL_DSI_ConfigFlowControl(&hdsi, DSI_FLOW_CONTROL_BTA) != HAL_OK)
  {
    Error_Handler();
  }
  if (HAL_DSI_SetLowPowerRXFilter(&hdsi, 10000) != HAL_OK)
  {
    Error_Handler();
  }
  if (HAL_DSI_ConfigErrorMonitor(&hdsi, HAL_DSI_ERROR_NONE) != HAL_OK)
  {
    Error_Handler();
  }
  LPCmd.LPGenShortWriteNoP = DSI_LP_GSW0P_DISABLE;
  LPCmd.LPGenShortWriteOneP = DSI_LP_GSW1P_DISABLE;
  LPCmd.LPGenShortWriteTwoP = DSI_LP_GSW2P_DISABLE;
  LPCmd.LPGenShortReadNoP = DSI_LP_GSR0P_DISABLE;
  LPCmd.LPGenShortReadOneP = DSI_LP_GSR1P_DISABLE;
  LPCmd.LPGenShortReadTwoP = DSI_LP_GSR2P_DISABLE;
  LPCmd.LPGenLongWrite = DSI_LP_GLW_DISABLE;
  LPCmd.LPDcsShortWriteNoP = DSI_LP_DSW0P_DISABLE;
  LPCmd.LPDcsShortWriteOneP = DSI_LP_DSW1P_DISABLE;
  LPCmd.LPDcsShortReadNoP = DSI_LP_DSR0P_DISABLE;
  LPCmd.LPDcsLongWrite = DSI_LP_DLW_DISABLE;
  LPCmd.LPMaxReadPacket = DSI_LP_MRDP_DISABLE;
  LPCmd.AcknowledgeRequest = DSI_ACKNOWLEDGE_DISABLE;
  if (HAL_DSI_ConfigCommand(&hdsi, &LPCmd) != HAL_OK)
  {
    Error_Handler();
  }
  CmdCfg.VirtualChannelID = 0;
  CmdCfg.ColorCoding = DSI_RGB888;
  CmdCfg.CommandSize = 640;
  CmdCfg.TearingEffectSource = DSI_TE_EXTERNAL;
  CmdCfg.TearingEffectPolarity = DSI_TE_RISING_EDGE;
  CmdCfg.HSPolarity = DSI_HSYNC_ACTIVE_LOW;
  CmdCfg.VSPolarity = DSI_VSYNC_ACTIVE_LOW;
  CmdCfg.DEPolarity = DSI_DATA_ENABLE_ACTIVE_HIGH;
  CmdCfg.VSyncPol = DSI_VSYNC_FALLING;
  CmdCfg.AutomaticRefresh = DSI_AR_ENABLE;
  CmdCfg.TEAcknowledgeRequest = DSI_TE_ACKNOWLEDGE_DISABLE;
  if (HAL_DSI_ConfigAdaptedCommandMode(&hdsi, &CmdCfg) != HAL_OK)
  {
    Error_Handler();
  }
  if (HAL_DSI_SetGenericVCID(&hdsi, 0) != HAL_OK)
  {
    Error_Handler();
  }

}

static void MX_LTDC_Init(void)
{

  LTDC_LayerCfgTypeDef pLayerCfg = {0};
  LTDC_LayerCfgTypeDef pLayerCfg1 = {0};

  hltdc.Instance = LTDC;
  hltdc.Init.HSPolarity = LTDC_HSPOLARITY_AL;
  hltdc.Init.VSPolarity = LTDC_VSPOLARITY_AL;
  hltdc.Init.DEPolarity = LTDC_DEPOLARITY_AL;
  hltdc.Init.PCPolarity = LTDC_PCPOLARITY_IPC;
  hltdc.Init.HorizontalSync = 7;
  hltdc.Init.VerticalSync = 3;
  hltdc.Init.AccumulatedHBP = 14;
  hltdc.Init.AccumulatedVBP = 5;
  hltdc.Init.AccumulatedActiveW = 654;
  hltdc.Init.AccumulatedActiveH = 485;
  hltdc.Init.TotalWidth = 660;
  hltdc.Init.TotalHeigh = 487;
  hltdc.Init.Backcolor.Blue = 0;
  hltdc.Init.Backcolor.Green = 0;
  hltdc.Init.Backcolor.Red = 0;
  if (HAL_LTDC_Init(&hltdc) != HAL_OK)
  {
    Error_Handler();
  }
  pLayerCfg.WindowX0 = 0;
  pLayerCfg.WindowX1 = 0;
  pLayerCfg.WindowY0 = 0;
  pLayerCfg.WindowY1 = 0;
  pLayerCfg.PixelFormat = LTDC_PIXEL_FORMAT_ARGB8888;
  pLayerCfg.Alpha = 0;
  pLayerCfg.Alpha0 = 0;
  pLayerCfg.BlendingFactor1 = LTDC_BLENDING_FACTOR1_CA;
  pLayerCfg.BlendingFactor2 = LTDC_BLENDING_FACTOR2_CA;
  pLayerCfg.FBStartAdress = 0;
  pLayerCfg.ImageWidth = 0;
  pLayerCfg.ImageHeight = 0;
  pLayerCfg.Backcolor.Blue = 0;
  pLayerCfg.Backcolor.Green = 0;
  pLayerCfg.Backcolor.Red = 0;
  if (HAL_LTDC_ConfigLayer(&hltdc, &pLayerCfg, 0) != HAL_OK)
  {
    Error_Handler();
  }
  pLayerCfg1.WindowX0 = 0;
  pLayerCfg1.WindowX1 = 0;
  pLayerCfg1.WindowY0 = 0;
  pLayerCfg1.WindowY1 = 0;
  pLayerCfg1.PixelFormat = LTDC_PIXEL_FORMAT_ARGB8888;
  pLayerCfg1.Alpha = 0;
  pLayerCfg1.Alpha0 = 0;
  pLayerCfg1.BlendingFactor1 = LTDC_BLENDING_FACTOR1_CA;
  pLayerCfg1.BlendingFactor2 = LTDC_BLENDING_FACTOR2_CA;
  pLayerCfg1.FBStartAdress = 0;
  pLayerCfg1.ImageWidth = 0;
  pLayerCfg1.ImageHeight = 0;
  pLayerCfg1.Backcolor.Blue = 0;
  pLayerCfg1.Backcolor.Green = 0;
  pLayerCfg1.Backcolor.Red = 0;
  if (HAL_LTDC_ConfigLayer(&hltdc, &pLayerCfg1, 1) != HAL_OK)
  {
    Error_Handler();
  }

}

static void MX_SDMMC2_SD_Init(void)
{

  hsd2.Instance = SDMMC2;
  hsd2.Init.ClockEdge = SDMMC_CLOCK_EDGE_RISING;
  hsd2.Init.ClockBypass = SDMMC_CLOCK_BYPASS_DISABLE;
  hsd2.Init.ClockPowerSave = SDMMC_CLOCK_POWER_SAVE_DISABLE;
  hsd2.Init.BusWide = SDMMC_BUS_WIDE_1B;
  hsd2.Init.HardwareFlowControl = SDMMC_HARDWARE_FLOW_CONTROL_DISABLE;
  hsd2.Init.ClockDiv = 0;

}

static void MX_TIM6_Init(void)
{

  TIM_MasterConfigTypeDef sMasterConfig = {0};

  htim6.Instance = TIM6;
  htim6.Init.Prescaler = 9999;
  htim6.Init.CounterMode = TIM_COUNTERMODE_UP;
  htim6.Init.Period = 9999;
  htim6.Init.AutoReloadPreload = TIM_AUTORELOAD_PRELOAD_DISABLE;
  if (HAL_TIM_Base_Init(&htim6) != HAL_OK)
  {
    Error_Handler();
  }
  sMasterConfig.MasterOutputTrigger = TIM_TRGO_RESET;
  sMasterConfig.MasterSlaveMode = TIM_MASTERSLAVEMODE_DISABLE;
  if (HAL_TIMEx_MasterConfigSynchronization(&htim6, &sMasterConfig) != HAL_OK)
  {
    Error_Handler();
  }

}

static void MX_TIM7_Init(void)
{

  TIM_MasterConfigTypeDef sMasterConfig = {0};

  htim7.Instance = TIM7;
  htim7.Init.Prescaler = 9999;
  htim7.Init.CounterMode = TIM_COUNTERMODE_UP;
  htim7.Init.Period = 9999;
  htim7.Init.AutoReloadPreload = TIM_AUTORELOAD_PRELOAD_DISABLE;
  if (HAL_TIM_Base_Init(&htim7) != HAL_OK)
  {
    Error_Handler();
  }
  sMasterConfig.MasterOutputTrigger = TIM_TRGO_RESET;
  sMasterConfig.MasterSlaveMode = TIM_MASTERSLAVEMODE_DISABLE;
  if (HAL_TIMEx_MasterConfigSynchronization(&htim7, &sMasterConfig) != HAL_OK)
  {
    Error_Handler();
  }

}

/* FMC initialization function */
static void MX_FMC_Init(void)
{

  FMC_SDRAM_TimingTypeDef SdramTiming = {0};

  /** Perform the SDRAM1 memory initialization sequence
  */
  hsdram1.Instance = FMC_SDRAM_DEVICE;
  /* hsdram1.Init */
  hsdram1.Init.SDBank = FMC_SDRAM_BANK2;
  hsdram1.Init.ColumnBitsNumber = FMC_SDRAM_COLUMN_BITS_NUM_8;
  hsdram1.Init.RowBitsNumber = FMC_SDRAM_ROW_BITS_NUM_13;
  hsdram1.Init.MemoryDataWidth = FMC_SDRAM_MEM_BUS_WIDTH_32;
  hsdram1.Init.InternalBankNumber = FMC_SDRAM_INTERN_BANKS_NUM_4;
  hsdram1.Init.CASLatency = FMC_SDRAM_CAS_LATENCY_1;
  hsdram1.Init.WriteProtection = FMC_SDRAM_WRITE_PROTECTION_DISABLE;
  hsdram1.Init.SDClockPeriod = FMC_SDRAM_CLOCK_DISABLE;
  hsdram1.Init.ReadBurst = FMC_SDRAM_RBURST_DISABLE;
  hsdram1.Init.ReadPipeDelay = FMC_SDRAM_RPIPE_DELAY_0;
  /* SdramTiming */
  SdramTiming.LoadToActiveDelay = 16;
  SdramTiming.ExitSelfRefreshDelay = 16;
  SdramTiming.SelfRefreshTime = 16;
  SdramTiming.RowCycleDelay = 16;
  SdramTiming.WriteRecoveryTime = 16;
  SdramTiming.RPDelay = 16;
  SdramTiming.RCDDelay = 16;

  if (HAL_SDRAM_Init(&hsdram1, &SdramTiming) != HAL_OK)
  {
    Error_Handler( );
  }

}

static void MX_GPIO_Init(void)
{
  GPIO_InitTypeDef GPIO_InitStruct = {0};

  /* GPIO Ports Clock Enable */
  __HAL_RCC_GPIOE_CLK_ENABLE();
  __HAL_RCC_GPIOB_CLK_ENABLE();
  __HAL_RCC_GPIOD_CLK_ENABLE();
  __HAL_RCC_GPIOG_CLK_ENABLE();
  __HAL_RCC_GPIOI_CLK_ENABLE();
  __HAL_RCC_GPIOF_CLK_ENABLE();
  __HAL_RCC_GPIOH_CLK_ENABLE();
  __HAL_RCC_GPIOA_CLK_ENABLE();
  __HAL_RCC_GPIOJ_CLK_ENABLE();

  /*Configure GPIO pin : PI13 */
  GPIO_InitStruct.Pin = GPIO_PIN_13;
  GPIO_InitStruct.Mode = GPIO_MODE_IT_RISING;
  GPIO_InitStruct.Pull = GPIO_NOPULL;
  HAL_GPIO_Init(GPIOI, &GPIO_InitStruct);

  /*Configure GPIO pin : PI15 */
  GPIO_InitStruct.Pin = GPIO_PIN_15;
  GPIO_InitStruct.Mode = GPIO_MODE_INPUT;
  GPIO_InitStruct.Pull = GPIO_NOPULL;
  HAL_GPIO_Init(GPIOI, &GPIO_InitStruct);

  /*Configure GPIO pin : PA0 */
  GPIO_InitStruct.Pin = GPIO_PIN_0;
  GPIO_InitStruct.Mode = GPIO_MODE_IT_RISING;
  GPIO_InitStruct.Pull = GPIO_NOPULL;
  HAL_GPIO_Init(GPIOA, &GPIO_InitStruct);

  /* EXTI interrupt init*/
  HAL_NVIC_SetPriority(EXTI0_IRQn, 0, 0);
  HAL_NVIC_EnableIRQ(EXTI0_IRQn);

  HAL_NVIC_SetPriority(EXTI15_10_IRQn, 0, 0);
  HAL_NVIC_EnableIRQ(EXTI15_10_IRQn);

}

/* USER CODE BEGIN 4 */
static void LCD_Config(void)
{
  uint32_t  lcd_status = LCD_OK;

  /* Initialize the LCD */
  lcd_status = BSP_LCD_Init();
  while(lcd_status != LCD_OK);

  BSP_LCD_LayerDefaultInit(0, LCD_FB_START_ADDRESS);

  /* Clear the LCD */
  BSP_LCD_Clear(LCD_COLOR_WHITE);

  /* Set LCD Example description */
  BSP_LCD_SetTextColor(LCD_COLOR_DARKBLUE);
  BSP_LCD_SetFont(&Font12);
  BSP_LCD_DisplayStringAt(50, BSP_LCD_GetYSize()- 15, (uint8_t *)"Copyright (c) Vitor Bernardino 2019", RIGHT_MODE);
  BSP_LCD_SetTextColor(LCD_COLOR_BLUE);
  BSP_LCD_FillRect(0, 0, BSP_LCD_GetXSize(), 30);
  BSP_LCD_SetTextColor(LCD_COLOR_WHITE);
  BSP_LCD_SetBackColor(LCD_COLOR_BLUE);
  BSP_LCD_SetFont(&Font24);
  BSP_LCD_DisplayStringAt(0, 5, (uint8_t *)"REVERSI PROJECT", CENTER_MODE);
  BSP_LCD_SetFont(&Font16);
  /*BSP_LCD_DisplayStringAt(0, 60, (uint8_t *)"This example shows how to measure the Junction", CENTER_MODE);
  BSP_LCD_DisplayStringAt(0, 75, (uint8_t *)"Temperature of the device via an Internal", CENTER_MODE);
  BSP_LCD_DisplayStringAt(0, 90, (uint8_t *)"Sensor and display the Value on the LCD", CENTER_MODE);*/

  BSP_LCD_SetTextColor(LCD_COLOR_BLACK);
  BSP_LCD_SetBackColor(LCD_COLOR_WHITE);
  BSP_LCD_SetFont(&Font24);
}

void HAL_TIM_PeriodElapsedCallback(TIM_HandleTypeDef *htim) { //comum para todos os timers

	if (htim->Instance == TIM6){
		tempCnt ++;
		timeTotal++;
		seconds++;
	}
	if (htim->Instance == TIM7){
		TIMEFLAG=0;
		ctdown--;
	}
}

/* USER CODE END 4 */

void Error_Handler(void)
{
  /* USER CODE BEGIN Error_Handler_Debug */
  /* User can add his own implementation to report the HAL error return state */
	while(1){
		BSP_LED_Toggle(LED_RED);
		HAL_Delay(250);
	}
  /* USER CODE END Error_Handler_Debug */
}

/************************ (C) COPYRIGHT STMicroelectronics *****END OF FILE****/
